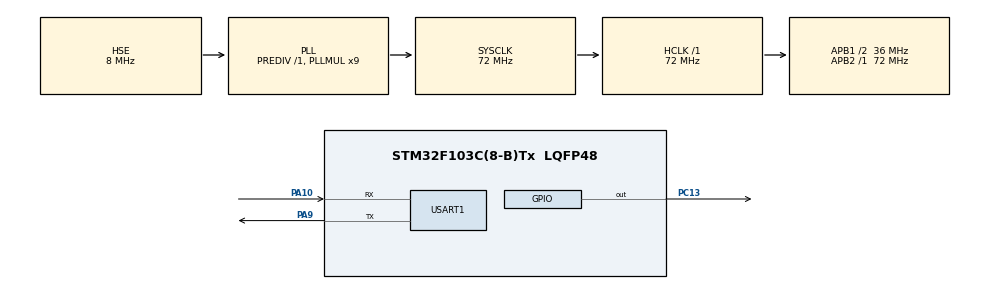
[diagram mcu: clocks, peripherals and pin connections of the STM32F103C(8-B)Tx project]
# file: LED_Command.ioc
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Mcu.Family=STM32F1
Mcu.Name=STM32F103C(8-B)Tx
Mcu.Package=LQFP48
NVIC.PriorityGroup=NVIC_PRIORITYGROUP_4
NVIC.RCC_IRQn=true\:0\:0\:false\:false\:true\:true\:false\:true
NVIC.USART1_IRQn=true\:0\:0\:false\:false\:true\:true\:true\:true
PA10.Mode=Asynchronous
PA10.Signal=USART1_RX
PA13.Mode=Serial_Wire
PA13.Signal=SYS_JTMS-SWDIO
PA14.Mode=Serial_Wire
PA14.Signal=SYS_JTCK-SWCLK
PA9.Mode=Asynchronous
PA9.Signal=USART1_TX
PC13-TAMPER-RTC.Signal=GPIO_Output
PC14-OSC32_IN.Mode=LSE-External-Oscillator
PC14-OSC32_IN.Signal=RCC_OSC32_IN
PC15-OSC32_OUT.Mode=LSE-External-Oscillator
PC15-OSC32_OUT.Signal=RCC_OSC32_OUT
PD0-OSC_IN.Mode=HSE-External-Oscillator
PD0-OSC_IN.Signal=RCC_OSC_IN
PD1-OSC_OUT.Mode=HSE-External-Oscillator
PD1-OSC_OUT.Signal=RCC_OSC_OUT
ProjectManager.HeapSize=0x200
ProjectManager.StackSize=0x400
ProjectManager.TargetToolchain=MDK-ARM V5.32
RCC.AHBFreq_Value=72000000
RCC.APB1CLKDivider=RCC_HCLK_DIV2
RCC.APB1Freq_Value=36000000
RCC.APB1TimFreq_Value=72000000
RCC.APB2Freq_Value=72000000
RCC.APB2TimFreq_Value=72000000
RCC.HCLKFreq_Value=72000000
RCC.PLLMUL=RCC_PLL_MUL9
RCC.PLLSourceVirtual=RCC_PLLSOURCE_HSE
RCC.SYSCLKFreq_VALUE=72000000
RCC.SYSCLKSource=RCC_SYSCLKSOURCE_PLLCLK
RCC.USBFreq_Value=72000000
USART1.VirtualMode=VM_ASYNC
board=custom

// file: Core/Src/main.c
/* USER CODE BEGIN Header */
/**
  ******************************************************************************
  * @file           : main.c
  * @brief          : Main program body
  ******************************************************************************
  * @attention
  *
  * Copyright (c) 2025 STMicroelectronics.
  * All rights reserved.
  *
  * This software is licensed under terms that can be found in the LICENSE file
  * in the root directory of this software component.
  * If no LICENSE file comes with this software, it is provided AS-IS.
  *
  ******************************************************************************
  */
/* USER CODE END Header */
#include "main.h"
#include "usart.h"
#include "gpio.h"

/* USER CODE BEGIN Includes */
#include <string.h>
/* USER CODE END Includes */

void SystemClock_Config(void);

/* USER CODE BEGIN 0 */
#define LED_ON() HAL_GPIO_WritePin(GPIOC, GPIO_PIN_13, GPIO_PIN_RESET);
#define LED_OFF() HAL_GPIO_WritePin(GPIOC, GPIO_PIN_13, GPIO_PIN_SET);

uint8_t rx_buffer[64];//缓冲储存代表命令的字符串
uint8_t rx_data = 0;//每个字节的数据
uint8_t rx_index = 0;//用来遍历buffer
uint8_t cmdstt = 0;//命令状态，为1时执行命令判断

void HAL_UART_RxCpltCallback(UART_HandleTypeDef *huart){
	if(huart->Instance == USART1){
//		rx_buffer[rx_index] = rx_data;//将读取到的数据写入缓冲区
//		rx_index ++;//遍历标志自增
		if(rx_data == '\n' || rx_data == '\r' || rx_index >= 63){//如果读取到换行或者超出缓冲区
			rx_buffer[rx_index] = '\0';//打结束标签
			cmdstt = 1;//执行命令判断
			rx_index = 0;//遍历标志归零
		}
		else{
			rx_buffer[rx_index] = rx_data;//将读取到的数据写入缓冲区
			rx_index ++;//遍历标志自增
		}
//		cmdstt = 1;
		HAL_UART_Receive_IT(&huart1, &rx_data, 1);//重新启动读取
	}
}

void CmdJudge(){
//	if(strcmp((char*)rx_buffer,"ON") == 0){
//		LED_ON();
//		HAL_UART_Transmit(&huart1, (uint8_t*)"LED ON\r\n", 8, 100);
//	}
//	else if(strcmp((char*)rx_buffer,"OFF") == 0){
//		LED_OFF();
//		HAL_UART_Transmit(&huart1, (uint8_t*)"LED OFF\r\n", 9, 100);
//	}
//	else{
//		HAL_UART_Transmit(&huart1, (uint8_t*)"ERROR\r\n", 7, 100);
//	}
//}
	if(strcmp((char*)rx_buffer,"ON") == 0){
		LED_ON();
		HAL_UART_Transmit_IT(&huart1, (uint8_t*)"LED ON\r\n", 8);
	}
	else if(strcmp((char*)rx_buffer,"OFF") == 0){
		LED_OFF();
		HAL_UART_Transmit_IT(&huart1, (uint8_t*)"LED OFF\r\n", 9);
	}
	else{
		HAL_UART_Transmit_IT(&huart1, (uint8_t*)"ERROR\r\n", 7);
	}
	cmdstt = 0;
}

/* USER CODE END 0 */

int main(void)
{

  /* MCU Configuration--------------------------------------------------------*/

  /* Reset of all peripherals, Initializes the Flash interface and the Systick. */
  HAL_Init();

  /* Configure the system clock */
  SystemClock_Config();

  /* Initialize all configured peripherals */
  MX_GPIO_Init();
  MX_USART1_UART_Init();
  /* USER CODE BEGIN 2 */
	HAL_UART_Receive_IT(&huart1, &rx_data, 1);
	HAL_UART_Transmit_IT(&huart1, (uint8_t*)"System Link\n", 12);
  /* USER CODE END 2 */

  /* Infinite loop */
  /* USER CODE BEGIN WHILE */
  while (1)
  {
		if(cmdstt){
			CmdJudge();
		}
		HAL_Delay(50);
    /* USER CODE END WHILE */

  }
}

void SystemClock_Config(void)
{
  RCC_OscInitTypeDef RCC_OscInitStruct = {0};
  RCC_ClkInitTypeDef RCC_ClkInitStruct = {0};

  /** Initializes the RCC Oscillators according to the specified parameters
  * in the RCC_OscInitTypeDef structure.
  */
  RCC_OscInitStruct.OscillatorType = RCC_OSCILLATORTYPE_HSE;
  RCC_OscInitStruct.HSEState = RCC_HSE_ON;
  RCC_OscInitStruct.HSEPredivValue = RCC_HSE_PREDIV_DIV1;
  RCC_OscInitStruct.HSIState = RCC_HSI_ON;
  RCC_OscInitStruct.PLL.PLLState = RCC_PLL_ON;
  RCC_OscInitStruct.PLL.PLLSource = RCC_PLLSOURCE_HSE;
  RCC_OscInitStruct.PLL.PLLMUL = RCC_PLL_MUL9;
  if (HAL_RCC_OscConfig(&RCC_OscInitStruct) != HAL_OK)
  {
    Error_Handler();
  }

  /** Initializes the CPU, AHB and APB buses clocks
  */
  RCC_ClkInitStruct.ClockType = RCC_CLOCKTYPE_HCLK|RCC_CLOCKTYPE_SYSCLK
                              |RCC_CLOCKTYPE_PCLK1|RCC_CLOCKTYPE_PCLK2;
  RCC_ClkInitStruct.SYSCLKSource = RCC_SYSCLKSOURCE_PLLCLK;
  RCC_ClkInitStruct.AHBCLKDivider = RCC_SYSCLK_DIV1;
  RCC_ClkInitStruct.APB1CLKDivider = RCC_HCLK_DIV2;
  RCC_ClkInitStruct.APB2CLKDivider = RCC_HCLK_DIV1;

  if (HAL_RCC_ClockConfig(&RCC_ClkInitStruct, FLASH_LATENCY_2) != HAL_OK)
  {
    Error_Handler();
  }
}

void Error_Handler(void)
{
  __disable_irq();
  while (1)
  {
  }
}
